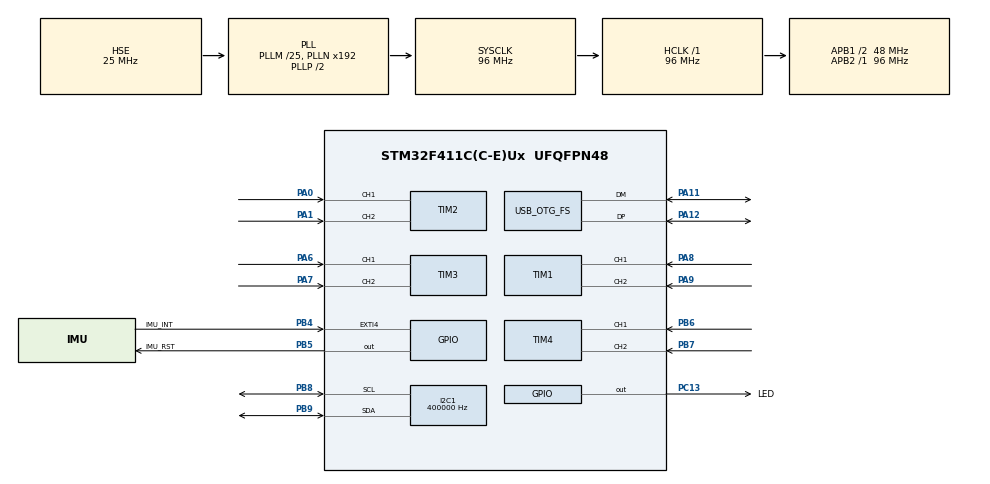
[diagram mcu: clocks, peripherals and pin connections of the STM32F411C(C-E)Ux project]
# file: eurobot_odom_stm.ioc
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FREERTOS.Tasks01=defaultTask,24,3000,StartDefaultTask,Default,NULL,Dynamic,NULL,NULL
FREERTOS.configCHECK_FOR_STACK_OVERFLOW=2
FREERTOS.configTOTAL_HEAP_SIZE=30000
FREERTOS.configUSE_MALLOC_FAILED_HOOK=1
FREERTOS.configUSE_NEWLIB_REENTRANT=1
I2C1.ClockSpeed=400000
I2C1.I2C_Mode=I2C_Fast
Mcu.Family=STM32F4
Mcu.Name=STM32F411C(C-E)Ux
Mcu.Package=UFQFPN48
NVIC.EXTI4_IRQn=true\:5\:0\:false\:false\:true\:true\:true\:true\:true
NVIC.OTG_FS_IRQn=true\:5\:0\:false\:false\:true\:false\:false\:true\:true
NVIC.PriorityGroup=NVIC_PRIORITYGROUP_4
NVIC.TIM1_TRG_COM_TIM11_IRQn=true\:0\:0\:false\:false\:true\:false\:false\:true\:true
NVIC.TimeBase=TIM1_TRG_COM_TIM11_IRQn
NVIC.TimeBaseIP=TIM11
PA0-WKUP.Signal=S_TIM2_CH1_ETR
PA1.Signal=S_TIM2_CH2
PA11.Mode=Device_Only
PA11.Signal=USB_OTG_FS_DM
PA12.Mode=Device_Only
PA12.Signal=USB_OTG_FS_DP
PA13.Mode=Serial_Wire
PA13.Signal=SYS_JTMS-SWDIO
PA14.Mode=Serial_Wire
PA14.Signal=SYS_JTCK-SWCLK
PA6.Signal=S_TIM3_CH1
PA7.Signal=S_TIM3_CH2
PA8.Signal=S_TIM1_CH1
PA9.Signal=S_TIM1_CH2
PB4.GPIO_Label=IMU_INT
PB4.GPIO_ModeDefaultEXTI=GPIO_MODE_IT_FALLING
PB4.GPIO_PuPd=GPIO_PULLUP
PB4.Signal=GPXTI4
PB5.GPIO_Label=IMU_RST
PB5.PinState=GPIO_PIN_SET
PB5.Signal=GPIO_Output
PB6.Signal=S_TIM4_CH1
PB7.Signal=S_TIM4_CH2
PB8.Mode=I2C
PB8.Signal=I2C1_SCL
PB9.Mode=I2C
PB9.Signal=I2C1_SDA
PC13-ANTI_TAMP.GPIO_Label=LED
PC13-ANTI_TAMP.PinState=GPIO_PIN_SET
PC13-ANTI_TAMP.Signal=GPIO_Output
PH0\ -\ OSC_IN.Mode=HSE-External-Oscillator
PH0\ -\ OSC_IN.Signal=RCC_OSC_IN
PH1\ -\ OSC_OUT.Mode=HSE-External-Oscillator
PH1\ -\ OSC_OUT.Signal=RCC_OSC_OUT
ProjectManager.HeapSize=0x200
ProjectManager.StackSize=0x400
ProjectManager.TargetToolchain=STM32CubeIDE
RCC.AHBFreq_Value=96000000
RCC.APB1CLKDivider=RCC_HCLK_DIV2
RCC.APB1Freq_Value=48000000
RCC.APB1TimFreq_Value=96000000
RCC.APB2Freq_Value=96000000
RCC.APB2TimFreq_Value=96000000
RCC.CortexFreq_Value=96000000
RCC.HCLKFreq_Value=96000000
RCC.HSE_VALUE=25000000
RCC.HSI_VALUE=16000000
RCC.LSE_VALUE=32768
RCC.PLLM=25
RCC.PLLN=192
RCC.PLLQ=4
RCC.SYSCLKFreq_VALUE=96000000
RCC.SYSCLKSource=RCC_SYSCLKSOURCE_PLLCLK
RCC.USBFreq_Value=48000000
RCC.VCOOutputFreq_Value=192000000
SH.S_TIM1_CH1.0=TIM1_CH1,Encoder_Interface
SH.S_TIM1_CH2.0=TIM1_CH2,Encoder_Interface
SH.S_TIM2_CH1_ETR.0=TIM2_CH1,Encoder_Interface
SH.S_TIM2_CH2.0=TIM2_CH2,Encoder_Interface
SH.S_TIM3_CH1.0=TIM3_CH1,Encoder_Interface
SH.S_TIM3_CH2.0=TIM3_CH2,Encoder_Interface
SH.S_TIM4_CH1.0=TIM4_CH1,Encoder_Interface
SH.S_TIM4_CH2.0=TIM4_CH2,Encoder_Interface
TIM1.EncoderMode=TIM_ENCODERMODE_TI12
TIM1.IC1Filter=5
TIM1.IC2Filter=5
TIM2.EncoderMode=TIM_ENCODERMODE_TI12
TIM2.IC1Filter=5
TIM2.IC2Filter=5
TIM3.EncoderMode=TIM_ENCODERMODE_TI12
TIM3.IC1Filter=5
TIM3.IC2Filter=5
TIM4.EncoderMode=TIM_ENCODERMODE_TI12
TIM4.IC1Filter=5
TIM4.IC2Filter=5
USB_DEVICE.CLASS_NAME_FS=CDC
USB_DEVICE.VirtualMode=Cdc
USB_DEVICE.VirtualMode-CDC_FS=Cdc
USB_DEVICE.VirtualModeFS=Cdc_FS
USB_OTG_FS.VirtualMode=Device_Only
VP_FREERTOS_VS_CMSIS_V2.Mode=CMSIS_V2
VP_SYS_VS_tim11.Mode=TIM11
VP_USB_DEVICE_VS_USB_DEVICE_CDC_FS.Mode=CDC_FS
board=custom

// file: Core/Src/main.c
/* USER CODE BEGIN Header */
/**
  ******************************************************************************
  * @file           : main.c
  * @brief          : Main program body
  ******************************************************************************
  * @attention
  *
  * Copyright (c) 2026 STMicroelectronics.
  * All rights reserved.
  *
  * This software is licensed under terms that can be found in the LICENSE file
  * in the root directory of this software component.
  * If no LICENSE file comes with this software, it is provided AS-IS.
  *
  ******************************************************************************
  */
/*
 * ===== 中文說明 =====
 * CubeMX 產生的程式進入點：初始化時脈和所有周邊，建立 FreeRTOS task，然後交給 scheduler。
 * 我們自己的程式只從兩個地方接進來：
 *   - USER CODE 2 裡的 app_init()
 *   - StartDefaultTask() 裡的 app_task()
 * 重新產生 code 時，只有 USER CODE BEGIN / END 之間的內容會保留。
 *
 * 函式：
 *   main()                    開機流程：HAL_Init → 設時脈 → 初始化周邊 → app_init()
 *                             → 建立 defaultTask → 啟動 FreeRTOS（不會返回）。
 *   SystemClock_Config()      設定時脈樹：板上 25 MHz 石英（HSE）經 PLL → SYSCLK 96 MHz，
 *                             APB1 48 MHz、APB2 96 MHz、USB 48 MHz（USB 一定要剛好 48 MHz）。
 *   MX_TIM1_Init()            TIM1 設成 Encoder mode（pod3，PA8 / PA9）。
 *   MX_TIM2_Init()            TIM2 設成 Encoder mode（pod1，PA0 / PA1，32-bit 計數器）。
 *   MX_TIM3_Init()            TIM3 設成 Encoder mode（pod2，PA6 / PA7）。
 *   MX_TIM4_Init()            TIM4 設成 Encoder mode（pod4，PB6 / PB7）。
 *   MX_I2C1_Init()            I2C1 設成 400 kHz，接 BNO055（PB8 SCL / PB9 SDA）。
 *   MX_GPIO_Init()            開 GPIO A/B/C/H 的時脈，設定板上 LED（PC13，低電位亮，預設熄滅）、
 *                             IMU 的 INT（PB4，下降緣中斷，BNO055 用不到）和 RST（PB5，輸出、預設 High）。
 *                             周邊腳位的設定在 stm32f4xx_hal_msp.c。
 *   StartDefaultTask()        先 MX_USB_DEVICE_Init() 啟動 USB（Type-C 當虛擬 COM 埠），
 *                             再呼叫 app_task()，不會返回。
 *   HAL_TIM_PeriodElapsedCallback()
 *                             Timer 更新中斷的 callback。TIM11 每 1 ms 觸發一次，
 *                             呼叫 HAL_IncTick() 讓 HAL_GetTick() 前進。
 *   Error_Handler()           出錯時關中斷並停在無窮迴圈。用 debugger 暫停就能看出卡在哪。
 *   assert_failed()           定義 USE_FULL_ASSERT 時，HAL 參數檢查失敗會呼叫這裡。目前是空的。
 */
/* USER CODE END Header */
#include "main.h"
#include "cmsis_os.h"
#include "usb_device.h"

/* USER CODE BEGIN Includes */
#include "app.h"
/* USER CODE END Includes */

I2C_HandleTypeDef hi2c1;

TIM_HandleTypeDef htim1;
TIM_HandleTypeDef htim2;
TIM_HandleTypeDef htim3;
TIM_HandleTypeDef htim4;

/* Definitions for defaultTask */
osThreadId_t defaultTaskHandle;
const osThreadAttr_t defaultTask_attributes = {
  .name = "defaultTask",
  .stack_size = 3000 * 4,
  .priority = (osPriority_t) osPriorityNormal,
};

void SystemClock_Config(void);
static void MX_GPIO_Init(void);
static void MX_I2C1_Init(void);
static void MX_TIM1_Init(void);
static void MX_TIM2_Init(void);
static void MX_TIM3_Init(void);
static void MX_TIM4_Init(void);
void StartDefaultTask(void *argument);

int main(void)
{

  /* MCU Configuration--------------------------------------------------------*/

  /* Reset of all peripherals, Initializes the Flash interface and the Systick. */
  HAL_Init();

  /* Configure the system clock */
  SystemClock_Config();

  /* Initialize all configured peripherals */
  MX_GPIO_Init();
  MX_I2C1_Init();
  MX_TIM1_Init();
  MX_TIM2_Init();
  MX_TIM3_Init();
  MX_TIM4_Init();
  /* USER CODE BEGIN 2 */
  app_init();
  /* USER CODE END 2 */

  /* Init scheduler */
  osKernelInitialize();

  /* Create the thread(s) */
  /* creation of defaultTask */
  defaultTaskHandle = osThreadNew(StartDefaultTask, NULL, &defaultTask_attributes);

  /* Start scheduler */
  osKernelStart();

  /* We should never get here as control is now taken by the scheduler */

  /* Infinite loop */
  while (1)
  {

    /* USER CODE BEGIN 3 */
    /* FreeRTOS 啟動後不會執行到這裡，主程式在 app_task()（StartDefaultTask 裡） */
  }
  /* USER CODE END 3 */
}

void SystemClock_Config(void)
{
  RCC_OscInitTypeDef RCC_OscInitStruct = {0};
  RCC_ClkInitTypeDef RCC_ClkInitStruct = {0};

  /** Configure the main internal regulator output voltage
  */
  __HAL_RCC_PWR_CLK_ENABLE();
  __HAL_PWR_VOLTAGESCALING_CONFIG(PWR_REGULATOR_VOLTAGE_SCALE1);

  /** Initializes the RCC Oscillators according to the specified parameters
  * in the RCC_OscInitTypeDef structure.
  */
  RCC_OscInitStruct.OscillatorType = RCC_OSCILLATORTYPE_HSE;
  RCC_OscInitStruct.HSEState = RCC_HSE_ON;
  RCC_OscInitStruct.PLL.PLLState = RCC_PLL_ON;
  RCC_OscInitStruct.PLL.PLLSource = RCC_PLLSOURCE_HSE;
  RCC_OscInitStruct.PLL.PLLM = 25;
  RCC_OscInitStruct.PLL.PLLN = 192;
  RCC_OscInitStruct.PLL.PLLP = RCC_PLLP_DIV2;
  RCC_OscInitStruct.PLL.PLLQ = 4;
  if (HAL_RCC_OscConfig(&RCC_OscInitStruct) != HAL_OK)
  {
    Error_Handler();
  }

  /** Initializes the CPU, AHB and APB buses clocks
  */
  RCC_ClkInitStruct.ClockType = RCC_CLOCKTYPE_HCLK|RCC_CLOCKTYPE_SYSCLK
                              |RCC_CLOCKTYPE_PCLK1|RCC_CLOCKTYPE_PCLK2;
  RCC_ClkInitStruct.SYSCLKSource = RCC_SYSCLKSOURCE_PLLCLK;
  RCC_ClkInitStruct.AHBCLKDivider = RCC_SYSCLK_DIV1;
  RCC_ClkInitStruct.APB1CLKDivider = RCC_HCLK_DIV2;
  RCC_ClkInitStruct.APB2CLKDivider = RCC_HCLK_DIV1;

  if (HAL_RCC_ClockConfig(&RCC_ClkInitStruct, FLASH_LATENCY_3) != HAL_OK)
  {
    Error_Handler();
  }
}

static void MX_I2C1_Init(void)
{

  hi2c1.Instance = I2C1;
  hi2c1.Init.ClockSpeed = 400000;
  hi2c1.Init.DutyCycle = I2C_DUTYCYCLE_2;
  hi2c1.Init.OwnAddress1 = 0;
  hi2c1.Init.AddressingMode = I2C_ADDRESSINGMODE_7BIT;
  hi2c1.Init.DualAddressMode = I2C_DUALADDRESS_DISABLE;
  hi2c1.Init.OwnAddress2 = 0;
  hi2c1.Init.GeneralCallMode = I2C_GENERALCALL_DISABLE;
  hi2c1.Init.NoStretchMode = I2C_NOSTRETCH_DISABLE;
  if (HAL_I2C_Init(&hi2c1) != HAL_OK)
  {
    Error_Handler();
  }

}

static void MX_TIM1_Init(void)
{

  TIM_Encoder_InitTypeDef sConfig = {0};
  TIM_MasterConfigTypeDef sMasterConfig = {0};

  htim1.Instance = TIM1;
  htim1.Init.Prescaler = 0;
  htim1.Init.CounterMode = TIM_COUNTERMODE_UP;
  htim1.Init.Period = 65535;
  htim1.Init.ClockDivision = TIM_CLOCKDIVISION_DIV1;
  htim1.Init.RepetitionCounter = 0;
  htim1.Init.AutoReloadPreload = TIM_AUTORELOAD_PRELOAD_DISABLE;
  sConfig.EncoderMode = TIM_ENCODERMODE_TI12;
  sConfig.IC1Polarity = TIM_ICPOLARITY_RISING;
  sConfig.IC1Selection = TIM_ICSELECTION_DIRECTTI;
  sConfig.IC1Prescaler = TIM_ICPSC_DIV1;
  sConfig.IC1Filter = 5;
  sConfig.IC2Polarity = TIM_ICPOLARITY_RISING;
  sConfig.IC2Selection = TIM_ICSELECTION_DIRECTTI;
  sConfig.IC2Prescaler = TIM_ICPSC_DIV1;
  sConfig.IC2Filter = 5;
  if (HAL_TIM_Encoder_Init(&htim1, &sConfig) != HAL_OK)
  {
    Error_Handler();
  }
  sMasterConfig.MasterOutputTrigger = TIM_TRGO_RESET;
  sMasterConfig.MasterSlaveMode = TIM_MASTERSLAVEMODE_DISABLE;
  if (HAL_TIMEx_MasterConfigSynchronization(&htim1, &sMasterConfig) != HAL_OK)
  {
    Error_Handler();
  }

}

static void MX_TIM2_Init(void)
{

  TIM_Encoder_InitTypeDef sConfig = {0};
  TIM_MasterConfigTypeDef sMasterConfig = {0};

  htim2.Instance = TIM2;
  htim2.Init.Prescaler = 0;
  htim2.Init.CounterMode = TIM_COUNTERMODE_UP;
  htim2.Init.Period = 4294967295;
  htim2.Init.ClockDivision = TIM_CLOCKDIVISION_DIV1;
  htim2.Init.AutoReloadPreload = TIM_AUTORELOAD_PRELOAD_DISABLE;
  sConfig.EncoderMode = TIM_ENCODERMODE_TI12;
  sConfig.IC1Polarity = TIM_ICPOLARITY_RISING;
  sConfig.IC1Selection = TIM_ICSELECTION_DIRECTTI;
  sConfig.IC1Prescaler = TIM_ICPSC_DIV1;
  sConfig.IC1Filter = 5;
  sConfig.IC2Polarity = TIM_ICPOLARITY_RISING;
  sConfig.IC2Selection = TIM_ICSELECTION_DIRECTTI;
  sConfig.IC2Prescaler = TIM_ICPSC_DIV1;
  sConfig.IC2Filter = 5;
  if (HAL_TIM_Encoder_Init(&htim2, &sConfig) != HAL_OK)
  {
    Error_Handler();
  }
  sMasterConfig.MasterOutputTrigger = TIM_TRGO_RESET;
  sMasterConfig.MasterSlaveMode = TIM_MASTERSLAVEMODE_DISABLE;
  if (HAL_TIMEx_MasterConfigSynchronization(&htim2, &sMasterConfig) != HAL_OK)
  {
    Error_Handler();
  }

}

static void MX_TIM3_Init(void)
{

  TIM_Encoder_InitTypeDef sConfig = {0};
  TIM_MasterConfigTypeDef sMasterConfig = {0};

  htim3.Instance = TIM3;
  htim3.Init.Prescaler = 0;
  htim3.Init.CounterMode = TIM_COUNTERMODE_UP;
  htim3.Init.Period = 65535;
  htim3.Init.ClockDivision = TIM_CLOCKDIVISION_DIV1;
  htim3.Init.AutoReloadPreload = TIM_AUTORELOAD_PRELOAD_DISABLE;
  sConfig.EncoderMode = TIM_ENCODERMODE_TI12;
  sConfig.IC1Polarity = TIM_ICPOLARITY_RISING;
  sConfig.IC1Selection = TIM_ICSELECTION_DIRECTTI;
  sConfig.IC1Prescaler = TIM_ICPSC_DIV1;
  sConfig.IC1Filter = 5;
  sConfig.IC2Polarity = TIM_ICPOLARITY_RISING;
  sConfig.IC2Selection = TIM_ICSELECTION_DIRECTTI;
  sConfig.IC2Prescaler = TIM_ICPSC_DIV1;
  sConfig.IC2Filter = 5;
  if (HAL_TIM_Encoder_Init(&htim3, &sConfig) != HAL_OK)
  {
    Error_Handler();
  }
  sMasterConfig.MasterOutputTrigger = TIM_TRGO_RESET;
  sMasterConfig.MasterSlaveMode = TIM_MASTERSLAVEMODE_DISABLE;
  if (HAL_TIMEx_MasterConfigSynchronization(&htim3, &sMasterConfig) != HAL_OK)
  {
    Error_Handler();
  }

}

static void MX_TIM4_Init(void)
{

  TIM_Encoder_InitTypeDef sConfig = {0};
  TIM_MasterConfigTypeDef sMasterConfig = {0};

  htim4.Instance = TIM4;
  htim4.Init.Prescaler = 0;
  htim4.Init.CounterMode = TIM_COUNTERMODE_UP;
  htim4.Init.Period = 65535;
  htim4.Init.ClockDivision = TIM_CLOCKDIVISION_DIV1;
  htim4.Init.AutoReloadPreload = TIM_AUTORELOAD_PRELOAD_DISABLE;
  sConfig.EncoderMode = TIM_ENCODERMODE_TI12;
  sConfig.IC1Polarity = TIM_ICPOLARITY_RISING;
  sConfig.IC1Selection = TIM_ICSELECTION_DIRECTTI;
  sConfig.IC1Prescaler = TIM_ICPSC_DIV1;
  sConfig.IC1Filter = 5;
  sConfig.IC2Polarity = TIM_ICPOLARITY_RISING;
  sConfig.IC2Selection = TIM_ICSELECTION_DIRECTTI;
  sConfig.IC2Prescaler = TIM_ICPSC_DIV1;
  sConfig.IC2Filter = 5;
  if (HAL_TIM_Encoder_Init(&htim4, &sConfig) != HAL_OK)
  {
    Error_Handler();
  }
  sMasterConfig.MasterOutputTrigger = TIM_TRGO_RESET;
  sMasterConfig.MasterSlaveMode = TIM_MASTERSLAVEMODE_DISABLE;
  if (HAL_TIMEx_MasterConfigSynchronization(&htim4, &sMasterConfig) != HAL_OK)
  {
    Error_Handler();
  }

}

static void MX_GPIO_Init(void)
{
  GPIO_InitTypeDef GPIO_InitStruct = {0};

  /* GPIO Ports Clock Enable */
  __HAL_RCC_GPIOC_CLK_ENABLE();
  __HAL_RCC_GPIOH_CLK_ENABLE();
  __HAL_RCC_GPIOA_CLK_ENABLE();
  __HAL_RCC_GPIOB_CLK_ENABLE();

  /*Configure GPIO pin Output Level */
  HAL_GPIO_WritePin(LED_GPIO_Port, LED_Pin, GPIO_PIN_SET);

  /*Configure GPIO pin Output Level */
  HAL_GPIO_WritePin(IMU_RST_GPIO_Port, IMU_RST_Pin, GPIO_PIN_SET);

  /*Configure GPIO pin : LED_Pin */
  GPIO_InitStruct.Pin = LED_Pin;
  GPIO_InitStruct.Mode = GPIO_MODE_OUTPUT_PP;
  GPIO_InitStruct.Pull = GPIO_NOPULL;
  GPIO_InitStruct.Speed = GPIO_SPEED_FREQ_LOW;
  HAL_GPIO_Init(LED_GPIO_Port, &GPIO_InitStruct);

  /*Configure GPIO pin : IMU_INT_Pin */
  GPIO_InitStruct.Pin = IMU_INT_Pin;
  GPIO_InitStruct.Mode = GPIO_MODE_IT_FALLING;
  GPIO_InitStruct.Pull = GPIO_PULLUP;
  HAL_GPIO_Init(IMU_INT_GPIO_Port, &GPIO_InitStruct);

  /*Configure GPIO pin : IMU_RST_Pin */
  GPIO_InitStruct.Pin = IMU_RST_Pin;
  GPIO_InitStruct.Mode = GPIO_MODE_OUTPUT_PP;
  GPIO_InitStruct.Pull = GPIO_NOPULL;
  GPIO_InitStruct.Speed = GPIO_SPEED_FREQ_LOW;
  HAL_GPIO_Init(IMU_RST_GPIO_Port, &GPIO_InitStruct);

  /* EXTI interrupt init*/
  HAL_NVIC_SetPriority(EXTI4_IRQn, 5, 0);
  HAL_NVIC_EnableIRQ(EXTI4_IRQn);

}

void StartDefaultTask(void *argument)
{
  /* init code for USB_DEVICE */
  MX_USB_DEVICE_Init();
  /* USER CODE BEGIN 5 */
  app_task();   /* 不會返回 */
  /* USER CODE END 5 */
}

void HAL_TIM_PeriodElapsedCallback(TIM_HandleTypeDef *htim)
{
  if (htim->Instance == TIM11)
  {
    HAL_IncTick();
  }
}

void Error_Handler(void)
{
  __disable_irq();
  while (1)
  {
  }
}

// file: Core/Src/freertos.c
/* USER CODE BEGIN Header */
/**
  ******************************************************************************
  * File Name          : freertos.c
  * Description        : Code for freertos applications
  ******************************************************************************
  * @attention
  *
  * Copyright (c) 2026 STMicroelectronics.
  * All rights reserved.
  *
  * This software is licensed under terms that can be found in the LICENSE file
  * in the root directory of this software component.
  * If no LICENSE file comes with this software, it is provided AS-IS.
  *
  ******************************************************************************
  */
/*
 * ===== 中文說明 =====
 * CubeMX 留給 FreeRTOS 應用程式碼的位置，例如 idle / tick hook、stack overflow hook，
 * 或是想放在這裡的額外 task。
 *
 * 唯一的 task（defaultTask）由 CubeMX 在 main.c 建立，不在這裡。
 * FreeRTOS 的設定（tick 1 kHz、heap 30000 bytes 等）在 Core/Inc/FreeRTOSConfig.h。
 *
 * 函式：
 *   vApplicationStackOverflowHook()  task 的 stack 爆掉時呼叫：記下 task 名稱、
 *                                    關中斷、LED（PC13）快閃並停住。
 *   vApplicationMallocFailedHook()   heap 配置失敗時呼叫：只累計次數，不停機。
 */
/* USER CODE END Header */

#include "FreeRTOS.h"
#include "task.h"
#include "main.h"

/* USER CODE BEGIN Variables */
/* 出錯時記在這裡，用 debugger 的 Live Expressions 觀察 */
const char *volatile rtos_overflow_task = NULL;  /* stack 爆掉的 task 名稱 */
volatile uint32_t    rtos_malloc_fail_count = 0; /* heap 配置失敗的次數 */
/* USER CODE END Variables */

/* Hook prototypes */
void vApplicationStackOverflowHook(xTaskHandle xTask, signed char *pcTaskName);
void vApplicationMallocFailedHook(void);

/* USER CODE BEGIN 4 */
/* FreeRTOS 切換 task 時發現 stack 爆掉會呼叫這裡。
 * 記憶體可能已經被破壞，不能繼續跑：關中斷、LED 快閃，停在這裡。 */
void vApplicationStackOverflowHook(xTaskHandle xTask, signed char *pcTaskName)
{
    (void)xTask;
    rtos_overflow_task = (const char *)pcTaskName;
    taskDISABLE_INTERRUPTS();
    for (;;) {
        LED_TOGGLE();
        for (volatile uint32_t i = 0; i < 1000000U; i++) {
            /* 忙等，不依賴任何中斷或 RTOS */
        }
    }
}
/* USER CODE END 4 */

/* USER CODE BEGIN 5 */
/* FreeRTOS 或 micro-ROS 的 heap 不夠時呼叫。
 * 呼叫端會拿到 NULL 並自己處理（micro-ROS 會重新連線），所以只記次數、不停機。
 * 這個數字不是 0，就表示 configTOTAL_HEAP_SIZE 該加大或有記憶體洩漏。 */
void vApplicationMallocFailedHook(void)
{
    rtos_malloc_fail_count++;
}
/* USER CODE END 5 */
